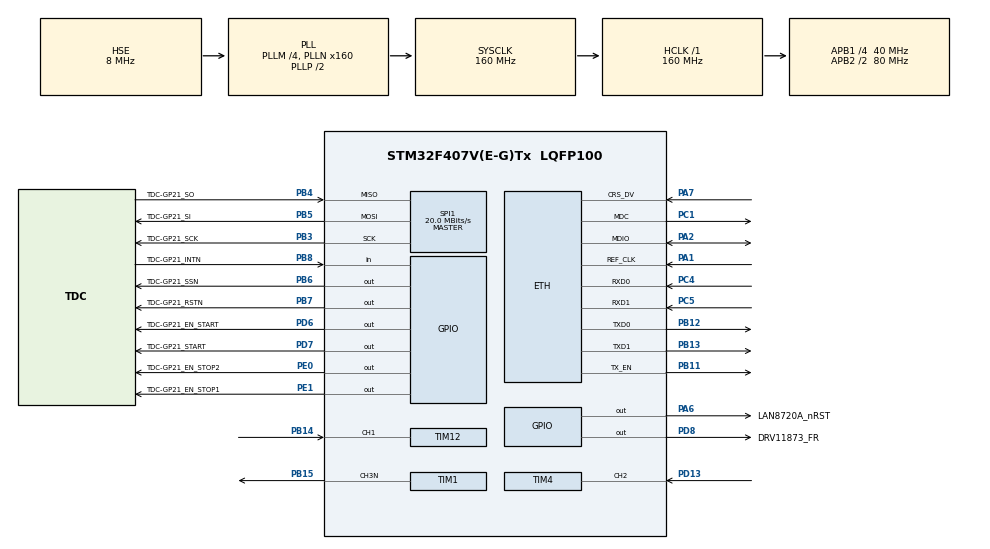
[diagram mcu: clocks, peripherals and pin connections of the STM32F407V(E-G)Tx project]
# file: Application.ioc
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ETH.MediaInterface=ETH_MEDIA_INTERFACE_RMII
ETH.PHY_DUPLEX_STATUS=0x0010
ETH.PHY_Name_RMII=userPHY
ETH.PHY_SPEED_STATUS=0x0004
ETH.PHY_SR=0x1F
ETH.PHY_User_Name=LAN8720A
FREERTOS.Tasks01=defaultTask,0,128,StartDefaultTask,Default,NULL
FREERTOS.configUSE_TIMERS=1
LWIP.IP_ADDRESS=192.168.001.160
LWIP.LWIP_DHCP=0
LWIP.LWIP_IGMP=1
LWIP.LWIP_MDNS=1
LWIP.LWIP_MDNS_RESPONDER=1
LWIP.LWIP_MULTICAST_TX_OPTIONS=1
LWIP.LWIP_NUM_NETIF_CLIENT_DATA=1
LWIP.LWIP_SO_RCVTIMEO=1
LWIP.LWIP_TCP_KEEPALIVE=1
LWIP.MDNS_MAX_SERVICES=1
LWIP.NETMASK_ADDRESS=255.255.255.000
LWIP.Version=v2.0.3_Cube
Mcu.Family=STM32F4
Mcu.Name=STM32F407V(E-G)Tx
Mcu.Package=LQFP100
NVIC.ETH_IRQn=true\:5\:0\:false\:false\:true\:true\:false
NVIC.PriorityGroup=NVIC_PRIORITYGROUP_4
NVIC.TIM1_TRG_COM_TIM11_IRQn=true\:5\:0\:false\:false\:true\:true\:true
NVIC.TIM4_IRQn=true\:5\:0\:false\:false\:true\:true\:true
NVIC.TIM8_BRK_TIM12_IRQn=true\:5\:0\:false\:false\:true\:true\:true
NVIC.TIM8_TRG_COM_TIM14_IRQn=true\:0\:0\:false\:false\:true\:false\:false
NVIC.TimeBase=TIM8_TRG_COM_TIM14_IRQn
NVIC.TimeBaseIP=TIM14
PA1.Mode=RMII
PA1.Signal=ETH_REF_CLK
PA2.Mode=RMII
PA2.Signal=ETH_MDIO
PA6.GPIO_Label=LAN8720A_nRST
PA6.Signal=GPIO_Output
PA7.Mode=RMII
PA7.Signal=ETH_CRS_DV
PB11.Mode=RMII
PB11.Signal=ETH_TX_EN
PB12.Mode=RMII
PB12.Signal=ETH_TXD0
PB13.Mode=RMII
PB13.Signal=ETH_TXD1
PB14.Signal=S_TIM12_CH1
PB15.Mode=PWM Generation3 CH3N
PB15.Signal=TIM1_CH3N
PB3.GPIO_Label=TDC-GP21_SCK
PB3.Mode=Full_Duplex_Master
PB3.Signal=SPI1_SCK
PB4.GPIO_Label=TDC-GP21_SO
PB4.Mode=Full_Duplex_Master
PB4.Signal=SPI1_MISO
PB5.GPIO_Label=TDC-GP21_SI
PB5.Mode=Full_Duplex_Master
PB5.Signal=SPI1_MOSI
PB6.GPIO_Label=TDC-GP21_SSN
PB6.GPIO_Speed=GPIO_SPEED_FREQ_VERY_HIGH
PB6.Signal=GPIO_Output
PB7.GPIO_Label=TDC-GP21_RSTN
PB7.Signal=GPIO_Output
PB8.GPIO_Label=TDC-GP21_INTN
PB8.Signal=GPIO_Input
PC1.Mode=RMII
PC1.Signal=ETH_MDC
PC4.Mode=RMII
PC4.Signal=ETH_RXD0
PC5.Mode=RMII
PC5.Signal=ETH_RXD1
PD13.Signal=S_TIM4_CH2
PD6.GPIO_Label=TDC-GP21_EN_START
PD6.Signal=GPIO_Output
PD7.GPIO_Label=TDC-GP21_START
PD7.GPIO_Speed=GPIO_SPEED_FREQ_VERY_HIGH
PD7.Signal=GPIO_Output
PD8.GPIO_Label=DRV11873_FR
PD8.Signal=GPIO_Output
PE0.GPIO_Label=TDC-GP21_EN_STOP2
PE0.Signal=GPIO_Output
PE1.GPIO_Label=TDC-GP21_EN_STOP1
PE1.Signal=GPIO_Output
PH0-OSC_IN.Mode=HSE-External-Oscillator
PH0-OSC_IN.Signal=RCC_OSC_IN
PH1-OSC_OUT.Mode=HSE-External-Oscillator
PH1-OSC_OUT.Signal=RCC_OSC_OUT
ProjectManager.HeapSize=0x200
ProjectManager.StackSize=0x400
ProjectManager.TargetToolchain=EWARM
RCC.48MHZClocksFreq_Value=80000000
RCC.AHBFreq_Value=160000000
RCC.APB1CLKDivider=RCC_HCLK_DIV4
RCC.APB1Freq_Value=40000000
RCC.APB1TimFreq_Value=80000000
RCC.APB2CLKDivider=RCC_HCLK_DIV2
RCC.APB2Freq_Value=80000000
RCC.APB2TimFreq_Value=160000000
RCC.CortexFreq_Value=160000000
RCC.HCLKFreq_Value=160000000
RCC.HSE_VALUE=8000000
RCC.HSI_VALUE=16000000
RCC.LSE_VALUE=32768
RCC.PLLM=4
RCC.PLLN=160
RCC.PLLSourceVirtual=RCC_PLLSOURCE_HSE
RCC.SYSCLKFreq_VALUE=160000000
RCC.SYSCLKSource=RCC_SYSCLKSOURCE_PLLCLK
RCC.VCOOutputFreq_Value=320000000
SH.S_TIM12_CH1.0=TIM12_CH1,Input_Capture1_from_TI1
SH.S_TIM4_CH2.0=TIM4_CH2,Input_Capture2_from_TI2
SPI1.BaudRatePrescaler=SPI_BAUDRATEPRESCALER_4
SPI1.CLKPhase=SPI_PHASE_2EDGE
SPI1.CalculateBaudRate=20.0 MBits/s
SPI1.Direction=SPI_DIRECTION_2LINES
SPI1.Mode=SPI_MODE_MASTER
SPI1.VirtualType=VM_MASTER
TIM1.Channel-PWM\ Generation3\ CH3N=TIM_CHANNEL_3
TIM1.Period=400
TIM1.Prescaler=19
TIM12.Channel-Input_Capture1_from_TI1=TIM_CHANNEL_1
TIM12.ICPolarity_CH1=TIM_INPUTCHANNELPOLARITY_BOTHEDGE
TIM12.Period=65535
TIM12.Prescaler=79
TIM2.Period=0xFFFFFFFF
TIM2.Prescaler=79
TIM4.Channel-Input_Capture2_from_TI2=TIM_CHANNEL_2
TIM4.Period=65535
TIM4.Prescaler=79
VP_FREERTOS_VS_ENABLE.Mode=Enabled
VP_LWIP_VS_Enabled.Mode=Enabled
VP_SYS_VS_tim14.Mode=TIM14
VP_TIM11_VS_ClockSourceINT.Mode=Enable_Timer
VP_TIM2_VS_ClockSourceINT.Mode=Internal
board=custom

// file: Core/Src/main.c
/**
  ******************************************************************************
  * @file           : main.c
  * @brief          : Main program body
  ******************************************************************************
  * This notice applies to any and all portions of this file
  * that are not between comment pairs USER CODE BEGIN and
  * USER CODE END. Other portions of this file, whether
  * inserted by the user or by software development tools
  * are owned by their respective copyright owners.
  *
  * Copyright (c) 2019 STMicroelectronics International N.V.
  * All rights reserved.
  *
  * Redistribution and use in source and binary forms, with or without
  * modification, are permitted, provided that the following conditions are met:
  *
  * 1. Redistribution of source code must retain the above copyright notice,
  *    this list of conditions and the following disclaimer.
  * 2. Redistributions in binary form must reproduce the above copyright notice,
  *    this list of conditions and the following disclaimer in the documentation
  *    and/or other materials provided with the distribution.
  * 3. Neither the name of STMicroelectronics nor the names of other
  *    contributors to this software may be used to endorse or promote products
  *    derived from this software without specific written permission.
  * 4. This software, including modifications and/or derivative works of this
  *    software, must execute solely and exclusively on microcontroller or
  *    microprocessor devices manufactured by or for STMicroelectronics.
  * 5. Redistribution and use of this software other than as permitted under
  *    this license is void and will automatically terminate your rights under
  *    this license.
  *
  * THIS SOFTWARE IS PROVIDED BY STMICROELECTRONICS AND CONTRIBUTORS "AS IS"
  * AND ANY EXPRESS, IMPLIED OR STATUTORY WARRANTIES, INCLUDING, BUT NOT
  * LIMITED TO, THE IMPLIED WARRANTIES OF MERCHANTABILITY, FITNESS FOR A
  * PARTICULAR PURPOSE AND NON-INFRINGEMENT OF THIRD PARTY INTELLECTUAL PROPERTY
  * RIGHTS ARE DISCLAIMED TO THE FULLEST EXTENT PERMITTED BY LAW. IN NO EVENT
  * SHALL STMICROELECTRONICS OR CONTRIBUTORS BE LIABLE FOR ANY DIRECT, INDIRECT,
  * INCIDENTAL, SPECIAL, EXEMPLARY, OR CONSEQUENTIAL DAMAGES (INCLUDING, BUT NOT
  * LIMITED TO, PROCUREMENT OF SUBSTITUTE GOODS OR SERVICES; LOSS OF USE, DATA,
  * OR PROFITS; OR BUSINESS INTERRUPTION) HOWEVER CAUSED AND ON ANY THEORY OF
  * LIABILITY, WHETHER IN CONTRACT, STRICT LIABILITY, OR TORT (INCLUDING
  * NEGLIGENCE OR OTHERWISE) ARISING IN ANY WAY OUT OF THE USE OF THIS SOFTWARE,
  * EVEN IF ADVISED OF THE POSSIBILITY OF SUCH DAMAGE.
  *
  ******************************************************************************
  */
#include "main.h"
#include "stm32f4xx_hal.h"
#include "cmsis_os.h"
#include "lwip.h"

/* USER CODE BEGIN Includes */

#include "encoder.h"
#include "motor.h"
#include "range_finder.h"
#include "device.h"
#include "ldcp.h"

/* USER CODE END Includes */

SPI_HandleTypeDef hspi1;

TIM_HandleTypeDef htim1;
TIM_HandleTypeDef htim2;
TIM_HandleTypeDef htim4;
TIM_HandleTypeDef htim11;
TIM_HandleTypeDef htim12;

osThreadId defaultTaskHandle;

/* USER CODE BEGIN PV */
/* Private variables ---------------------------------------------------------*/

/* USER CODE END PV */

void SystemClock_Config(void);
static void MX_GPIO_Init(void);
static void MX_TIM2_Init(void);
static void MX_TIM11_Init(void);
static void MX_TIM1_Init(void);
static void MX_TIM12_Init(void);
static void MX_TIM4_Init(void);
static void MX_SPI1_Init(void);
void StartDefaultTask(void const * argument);

void HAL_TIM_MspPostInit(TIM_HandleTypeDef *htim);

/* USER CODE BEGIN PFP */
/* Private function prototypes -----------------------------------------------*/

/* USER CODE END PFP */

int main(void)
{

  /* MCU Configuration----------------------------------------------------------*/

  /* Reset of all peripherals, Initializes the Flash interface and the Systick. */
  HAL_Init();

  /* Configure the system clock */
  SystemClock_Config();

  /* Initialize all configured peripherals */
  MX_GPIO_Init();
  MX_TIM2_Init();
  MX_TIM11_Init();
  MX_TIM1_Init();
  MX_TIM12_Init();
  MX_TIM4_Init();
  MX_SPI1_Init();

  /* Create the thread(s) */
  /* definition and creation of defaultTask */
  osThreadDef(defaultTask, StartDefaultTask, osPriorityNormal, 0, 256);
  defaultTaskHandle = osThreadCreate(osThread(defaultTask), NULL);

  /* Start scheduler */
  osKernelStart();

  /* We should never get here as control is now taken by the scheduler */

  /* Infinite loop */
  while (1)
  {

  }

}

void SystemClock_Config(void)
{

  RCC_OscInitTypeDef RCC_OscInitStruct;
  RCC_ClkInitTypeDef RCC_ClkInitStruct;

    /**Configure the main internal regulator output voltage
    */
  __HAL_RCC_PWR_CLK_ENABLE();

  __HAL_PWR_VOLTAGESCALING_CONFIG(PWR_REGULATOR_VOLTAGE_SCALE1);

    /**Initializes the CPU, AHB and APB busses clocks
    */
  RCC_OscInitStruct.OscillatorType = RCC_OSCILLATORTYPE_HSE;
  RCC_OscInitStruct.HSEState = RCC_HSE_ON;
  RCC_OscInitStruct.PLL.PLLState = RCC_PLL_ON;
  RCC_OscInitStruct.PLL.PLLSource = RCC_PLLSOURCE_HSE;
  RCC_OscInitStruct.PLL.PLLM = 4;
  RCC_OscInitStruct.PLL.PLLN = 160;
  RCC_OscInitStruct.PLL.PLLP = RCC_PLLP_DIV2;
  RCC_OscInitStruct.PLL.PLLQ = 4;
  if (HAL_RCC_OscConfig(&RCC_OscInitStruct) != HAL_OK)
  {
    _Error_Handler(__FILE__, __LINE__);
  }

    /**Initializes the CPU, AHB and APB busses clocks
    */
  RCC_ClkInitStruct.ClockType = RCC_CLOCKTYPE_HCLK|RCC_CLOCKTYPE_SYSCLK
                              |RCC_CLOCKTYPE_PCLK1|RCC_CLOCKTYPE_PCLK2;
  RCC_ClkInitStruct.SYSCLKSource = RCC_SYSCLKSOURCE_PLLCLK;
  RCC_ClkInitStruct.AHBCLKDivider = RCC_SYSCLK_DIV1;
  RCC_ClkInitStruct.APB1CLKDivider = RCC_HCLK_DIV4;
  RCC_ClkInitStruct.APB2CLKDivider = RCC_HCLK_DIV2;

  if (HAL_RCC_ClockConfig(&RCC_ClkInitStruct, FLASH_LATENCY_5) != HAL_OK)
  {
    _Error_Handler(__FILE__, __LINE__);
  }

    /**Configure the Systick interrupt time
    */
  HAL_SYSTICK_Config(HAL_RCC_GetHCLKFreq()/1000);

    /**Configure the Systick
    */
  HAL_SYSTICK_CLKSourceConfig(SYSTICK_CLKSOURCE_HCLK);

  /* SysTick_IRQn interrupt configuration */
  HAL_NVIC_SetPriority(SysTick_IRQn, 15, 0);
}

/* SPI1 init function */
static void MX_SPI1_Init(void)
{

  /* SPI1 parameter configuration*/
  hspi1.Instance = SPI1;
  hspi1.Init.Mode = SPI_MODE_MASTER;
  hspi1.Init.Direction = SPI_DIRECTION_2LINES;
  hspi1.Init.DataSize = SPI_DATASIZE_8BIT;
  hspi1.Init.CLKPolarity = SPI_POLARITY_LOW;
  hspi1.Init.CLKPhase = SPI_PHASE_2EDGE;
  hspi1.Init.NSS = SPI_NSS_SOFT;
  hspi1.Init.BaudRatePrescaler = SPI_BAUDRATEPRESCALER_4;
  hspi1.Init.FirstBit = SPI_FIRSTBIT_MSB;
  hspi1.Init.TIMode = SPI_TIMODE_DISABLE;
  hspi1.Init.CRCCalculation = SPI_CRCCALCULATION_DISABLE;
  hspi1.Init.CRCPolynomial = 10;
  if (HAL_SPI_Init(&hspi1) != HAL_OK)
  {
    _Error_Handler(__FILE__, __LINE__);
  }

}

/* TIM1 init function */
static void MX_TIM1_Init(void)
{

  TIM_MasterConfigTypeDef sMasterConfig;
  TIM_OC_InitTypeDef sConfigOC;
  TIM_BreakDeadTimeConfigTypeDef sBreakDeadTimeConfig;

  htim1.Instance = TIM1;
  htim1.Init.Prescaler = 19;
  htim1.Init.CounterMode = TIM_COUNTERMODE_UP;
  htim1.Init.Period = 400;
  htim1.Init.ClockDivision = TIM_CLOCKDIVISION_DIV1;
  htim1.Init.RepetitionCounter = 0;
  if (HAL_TIM_PWM_Init(&htim1) != HAL_OK)
  {
    _Error_Handler(__FILE__, __LINE__);
  }

  sMasterConfig.MasterOutputTrigger = TIM_TRGO_RESET;
  sMasterConfig.MasterSlaveMode = TIM_MASTERSLAVEMODE_DISABLE;
  if (HAL_TIMEx_MasterConfigSynchronization(&htim1, &sMasterConfig) != HAL_OK)
  {
    _Error_Handler(__FILE__, __LINE__);
  }

  sConfigOC.OCMode = TIM_OCMODE_PWM1;
  sConfigOC.Pulse = 0;
  sConfigOC.OCPolarity = TIM_OCPOLARITY_HIGH;
  sConfigOC.OCNPolarity = TIM_OCNPOLARITY_HIGH;
  sConfigOC.OCFastMode = TIM_OCFAST_DISABLE;
  sConfigOC.OCIdleState = TIM_OCIDLESTATE_RESET;
  sConfigOC.OCNIdleState = TIM_OCNIDLESTATE_RESET;
  if (HAL_TIM_PWM_ConfigChannel(&htim1, &sConfigOC, TIM_CHANNEL_3) != HAL_OK)
  {
    _Error_Handler(__FILE__, __LINE__);
  }

  sBreakDeadTimeConfig.OffStateRunMode = TIM_OSSR_DISABLE;
  sBreakDeadTimeConfig.OffStateIDLEMode = TIM_OSSI_DISABLE;
  sBreakDeadTimeConfig.LockLevel = TIM_LOCKLEVEL_OFF;
  sBreakDeadTimeConfig.DeadTime = 0;
  sBreakDeadTimeConfig.BreakState = TIM_BREAK_DISABLE;
  sBreakDeadTimeConfig.BreakPolarity = TIM_BREAKPOLARITY_HIGH;
  sBreakDeadTimeConfig.AutomaticOutput = TIM_AUTOMATICOUTPUT_DISABLE;
  if (HAL_TIMEx_ConfigBreakDeadTime(&htim1, &sBreakDeadTimeConfig) != HAL_OK)
  {
    _Error_Handler(__FILE__, __LINE__);
  }

  HAL_TIM_MspPostInit(&htim1);

}

/* TIM2 init function */
static void MX_TIM2_Init(void)
{

  TIM_ClockConfigTypeDef sClockSourceConfig;
  TIM_MasterConfigTypeDef sMasterConfig;

  htim2.Instance = TIM2;
  htim2.Init.Prescaler = 79;
  htim2.Init.CounterMode = TIM_COUNTERMODE_UP;
  htim2.Init.Period = 0xFFFFFFFF;
  htim2.Init.ClockDivision = TIM_CLOCKDIVISION_DIV1;
  if (HAL_TIM_Base_Init(&htim2) != HAL_OK)
  {
    _Error_Handler(__FILE__, __LINE__);
  }

  sClockSourceConfig.ClockSource = TIM_CLOCKSOURCE_INTERNAL;
  if (HAL_TIM_ConfigClockSource(&htim2, &sClockSourceConfig) != HAL_OK)
  {
    _Error_Handler(__FILE__, __LINE__);
  }

  sMasterConfig.MasterOutputTrigger = TIM_TRGO_RESET;
  sMasterConfig.MasterSlaveMode = TIM_MASTERSLAVEMODE_DISABLE;
  if (HAL_TIMEx_MasterConfigSynchronization(&htim2, &sMasterConfig) != HAL_OK)
  {
    _Error_Handler(__FILE__, __LINE__);
  }

}

/* TIM4 init function */
static void MX_TIM4_Init(void)
{

  TIM_MasterConfigTypeDef sMasterConfig;
  TIM_IC_InitTypeDef sConfigIC;

  htim4.Instance = TIM4;
  htim4.Init.Prescaler = 79;
  htim4.Init.CounterMode = TIM_COUNTERMODE_UP;
  htim4.Init.Period = 65535;
  htim4.Init.ClockDivision = TIM_CLOCKDIVISION_DIV1;
  if (HAL_TIM_IC_Init(&htim4) != HAL_OK)
  {
    _Error_Handler(__FILE__, __LINE__);
  }

  sMasterConfig.MasterOutputTrigger = TIM_TRGO_RESET;
  sMasterConfig.MasterSlaveMode = TIM_MASTERSLAVEMODE_DISABLE;
  if (HAL_TIMEx_MasterConfigSynchronization(&htim4, &sMasterConfig) != HAL_OK)
  {
    _Error_Handler(__FILE__, __LINE__);
  }

  sConfigIC.ICPolarity = TIM_INPUTCHANNELPOLARITY_RISING;
  sConfigIC.ICSelection = TIM_ICSELECTION_DIRECTTI;
  sConfigIC.ICPrescaler = TIM_ICPSC_DIV1;
  sConfigIC.ICFilter = 0;
  if (HAL_TIM_IC_ConfigChannel(&htim4, &sConfigIC, TIM_CHANNEL_2) != HAL_OK)
  {
    _Error_Handler(__FILE__, __LINE__);
  }

}

/* TIM11 init function */
static void MX_TIM11_Init(void)
{

  htim11.Instance = TIM11;
  htim11.Init.Prescaler = 0;
  htim11.Init.CounterMode = TIM_COUNTERMODE_UP;
  htim11.Init.Period = 0;
  htim11.Init.ClockDivision = TIM_CLOCKDIVISION_DIV1;
  if (HAL_TIM_Base_Init(&htim11) != HAL_OK)
  {
    _Error_Handler(__FILE__, __LINE__);
  }

}

/* TIM12 init function */
static void MX_TIM12_Init(void)
{

  TIM_IC_InitTypeDef sConfigIC;

  htim12.Instance = TIM12;
  htim12.Init.Prescaler = 79;
  htim12.Init.CounterMode = TIM_COUNTERMODE_UP;
  htim12.Init.Period = 65535;
  htim12.Init.ClockDivision = TIM_CLOCKDIVISION_DIV1;
  if (HAL_TIM_IC_Init(&htim12) != HAL_OK)
  {
    _Error_Handler(__FILE__, __LINE__);
  }

  sConfigIC.ICPolarity = TIM_INPUTCHANNELPOLARITY_BOTHEDGE;
  sConfigIC.ICSelection = TIM_ICSELECTION_DIRECTTI;
  sConfigIC.ICPrescaler = TIM_ICPSC_DIV1;
  sConfigIC.ICFilter = 0;
  if (HAL_TIM_IC_ConfigChannel(&htim12, &sConfigIC, TIM_CHANNEL_1) != HAL_OK)
  {
    _Error_Handler(__FILE__, __LINE__);
  }

}

/** Configure pins as
        * Analog
        * Input
        * Output
        * EVENT_OUT
        * EXTI
*/
static void MX_GPIO_Init(void)
{

  GPIO_InitTypeDef GPIO_InitStruct;

  /* GPIO Ports Clock Enable */
  __HAL_RCC_GPIOH_CLK_ENABLE();
  __HAL_RCC_GPIOC_CLK_ENABLE();
  __HAL_RCC_GPIOA_CLK_ENABLE();
  __HAL_RCC_GPIOB_CLK_ENABLE();
  __HAL_RCC_GPIOD_CLK_ENABLE();
  __HAL_RCC_GPIOE_CLK_ENABLE();

  /*Configure GPIO pin Output Level */
  HAL_GPIO_WritePin(LAN8720A_nRST_GPIO_Port, LAN8720A_nRST_Pin, GPIO_PIN_RESET);

  /*Configure GPIO pin Output Level */
  HAL_GPIO_WritePin(GPIOD, DRV11873_FR_Pin|TDC_GP21_EN_START_Pin|TDC_GP21_START_Pin, GPIO_PIN_RESET);

  /*Configure GPIO pin Output Level */
  HAL_GPIO_WritePin(GPIOB, TDC_GP21_SSN_Pin|TDC_GP21_RSTN_Pin, GPIO_PIN_RESET);

  /*Configure GPIO pin Output Level */
  HAL_GPIO_WritePin(GPIOE, TDC_GP21_EN_STOP2_Pin|TDC_GP21_EN_STOP1_Pin, GPIO_PIN_RESET);

  /*Configure GPIO pin : LAN8720A_nRST_Pin */
  GPIO_InitStruct.Pin = LAN8720A_nRST_Pin;
  GPIO_InitStruct.Mode = GPIO_MODE_OUTPUT_PP;
  GPIO_InitStruct.Pull = GPIO_NOPULL;
  GPIO_InitStruct.Speed = GPIO_SPEED_FREQ_LOW;
  HAL_GPIO_Init(LAN8720A_nRST_GPIO_Port, &GPIO_InitStruct);

  /*Configure GPIO pins : DRV11873_FR_Pin TDC_GP21_EN_START_Pin */
  GPIO_InitStruct.Pin = DRV11873_FR_Pin|TDC_GP21_EN_START_Pin;
  GPIO_InitStruct.Mode = GPIO_MODE_OUTPUT_PP;
  GPIO_InitStruct.Pull = GPIO_NOPULL;
  GPIO_InitStruct.Speed = GPIO_SPEED_FREQ_LOW;
  HAL_GPIO_Init(GPIOD, &GPIO_InitStruct);

  /*Configure GPIO pin : TDC_GP21_START_Pin */
  GPIO_InitStruct.Pin = TDC_GP21_START_Pin;
  GPIO_InitStruct.Mode = GPIO_MODE_OUTPUT_PP;
  GPIO_InitStruct.Pull = GPIO_NOPULL;
  GPIO_InitStruct.Speed = GPIO_SPEED_FREQ_VERY_HIGH;
  HAL_GPIO_Init(TDC_GP21_START_GPIO_Port, &GPIO_InitStruct);

  /*Configure GPIO pin : TDC_GP21_SSN_Pin */
  GPIO_InitStruct.Pin = TDC_GP21_SSN_Pin;
  GPIO_InitStruct.Mode = GPIO_MODE_OUTPUT_PP;
  GPIO_InitStruct.Pull = GPIO_NOPULL;
  GPIO_InitStruct.Speed = GPIO_SPEED_FREQ_VERY_HIGH;
  HAL_GPIO_Init(TDC_GP21_SSN_GPIO_Port, &GPIO_InitStruct);

  /*Configure GPIO pin : TDC_GP21_RSTN_Pin */
  GPIO_InitStruct.Pin = TDC_GP21_RSTN_Pin;
  GPIO_InitStruct.Mode = GPIO_MODE_OUTPUT_PP;
  GPIO_InitStruct.Pull = GPIO_NOPULL;
  GPIO_InitStruct.Speed = GPIO_SPEED_FREQ_LOW;
  HAL_GPIO_Init(TDC_GP21_RSTN_GPIO_Port, &GPIO_InitStruct);

  /*Configure GPIO pin : TDC_GP21_INTN_Pin */
  GPIO_InitStruct.Pin = TDC_GP21_INTN_Pin;
  GPIO_InitStruct.Mode = GPIO_MODE_INPUT;
  GPIO_InitStruct.Pull = GPIO_NOPULL;
  HAL_GPIO_Init(TDC_GP21_INTN_GPIO_Port, &GPIO_InitStruct);

  /*Configure GPIO pins : TDC_GP21_EN_STOP2_Pin TDC_GP21_EN_STOP1_Pin */
  GPIO_InitStruct.Pin = TDC_GP21_EN_STOP2_Pin|TDC_GP21_EN_STOP1_Pin;
  GPIO_InitStruct.Mode = GPIO_MODE_OUTPUT_PP;
  GPIO_InitStruct.Pull = GPIO_NOPULL;
  GPIO_InitStruct.Speed = GPIO_SPEED_FREQ_LOW;
  HAL_GPIO_Init(GPIOE, &GPIO_InitStruct);

}

/* StartDefaultTask function */
void StartDefaultTask(void const * argument)
{
  /* init code for LWIP */
  MX_LWIP_Init();

  /* USER CODE BEGIN 5 */

 // Encoder_Init();   //启动定时器TIM12，用于确定位置
 // Motor_Init();    //创建定时器，定时调整电机转速
 // RangeFinder_Init(); //配置TDC的寄存器
  Device_Init();  //启动定时器TIM2，用于时间戳
  LDCP_Init();    //创建任务及队列

  /* Infinite loop */
  for(;;)
  {
    osDelay(1);
  }
  /* USER CODE END 5 */
}

void HAL_TIM_PeriodElapsedCallback(TIM_HandleTypeDef *htim)
{
  if (htim->Instance == TIM14) {
    HAL_IncTick();
  }
}

void _Error_Handler(char *file, int line)
{
  while(1)
  {
  }
}

/************************ (C) COPYRIGHT STMicroelectronics *****END OF FILE****/
